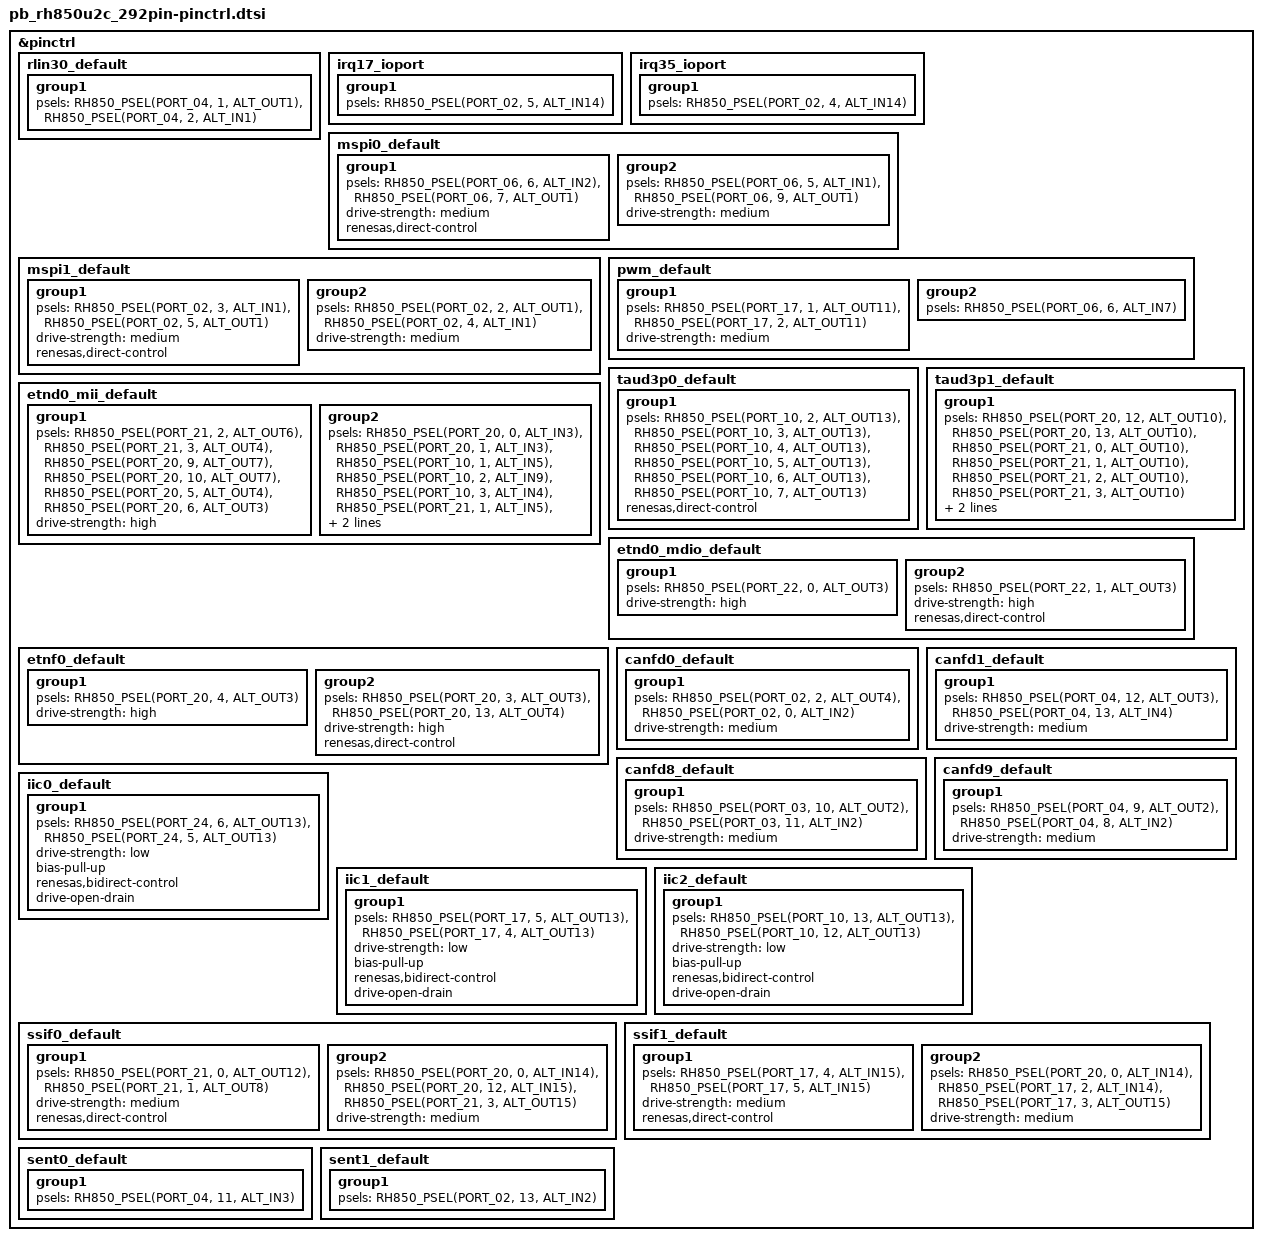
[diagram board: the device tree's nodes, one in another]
/*
 * Copyright (c) 2026 Renesas Electronics Corporation
 * SPDX-License-Identifier: Apache-2.0
 */

#include <dt-bindings/pinctrl/renesas/pinctrl-rh850u2c.h>

&pinctrl {
	rlin30_default: rlin30_default {
		group1 {
			psels = <RH850_PSEL(PORT_04, 1, ALT_OUT1)>,
				<RH850_PSEL(PORT_04, 2, ALT_IN1)>;
		};
	};

	irq17_ioport: irq17_ioport {
		group1 {
			psels = <RH850_PSEL(PORT_02, 5, ALT_IN14)>;
		};
	};

	irq35_ioport: irq35_ioport {
		group1 {
			psels = <RH850_PSEL(PORT_02, 4, ALT_IN14)>;
		};
	};

	mspi0_default: mspi0_default {
		group1 {
			psels = <RH850_PSEL(PORT_06, 6, ALT_IN2)>,
				<RH850_PSEL(PORT_06, 7, ALT_OUT1)>;
			drive-strength = "medium";
			renesas,direct-control;
		};

		group2 {
			psels = <RH850_PSEL(PORT_06, 5, ALT_IN1)>,
				<RH850_PSEL(PORT_06, 9, ALT_OUT1)>;
			drive-strength = "medium";
		};
	};

	mspi1_default: mspi1_default {
		group1 {
			psels = <RH850_PSEL(PORT_02, 3, ALT_IN1)>,
				<RH850_PSEL(PORT_02, 5, ALT_OUT1)>;
			drive-strength = "medium";
			renesas,direct-control;
		};

		group2 {
			psels = <RH850_PSEL(PORT_02, 2, ALT_OUT1)>,
				<RH850_PSEL(PORT_02, 4, ALT_IN1)>;
			drive-strength = "medium";
		};
	};

	pwm_default: pwm_default {
		group1 {
			psels = <RH850_PSEL(PORT_17, 1, ALT_OUT11)>,	/* ch1 */
				<RH850_PSEL(PORT_17, 2, ALT_OUT11)>;	/* ch2 */
			drive-strength = "medium";
		};

		group2 {
			psels = <RH850_PSEL(PORT_06, 6, ALT_IN7)>;	/* ch6 */
		};
	};

	taud3p0_default: taud3p0_default {
		group1 {
			psels = <RH850_PSEL(PORT_10, 2, ALT_OUT13)>,  /* U high */
				<RH850_PSEL(PORT_10, 3, ALT_OUT13)>,  /* U low  */
				<RH850_PSEL(PORT_10, 4, ALT_OUT13)>,  /* V high */
				<RH850_PSEL(PORT_10, 5, ALT_OUT13)>,  /* V low  */
				<RH850_PSEL(PORT_10, 6, ALT_OUT13)>,  /* W high */
				<RH850_PSEL(PORT_10, 7, ALT_OUT13)>;  /* W low  */
			renesas,direct-control;
		};
	};

	taud3p1_default: taud3p1_default {
		group1 {
			psels = <RH850_PSEL(PORT_20, 12, ALT_OUT10)>, /* U high */
				<RH850_PSEL(PORT_20, 13, ALT_OUT10)>, /* U low  */
				<RH850_PSEL(PORT_21, 0,  ALT_OUT10)>, /* V high */
				<RH850_PSEL(PORT_21, 1,  ALT_OUT10)>, /* V low  */
				<RH850_PSEL(PORT_21, 2,  ALT_OUT10)>, /* W high */
				<RH850_PSEL(PORT_21, 3,  ALT_OUT10)>; /* W low  */
			renesas,direct-control;
			drive-strength = "medium";
		};
	};

	etnd0_mii_default: etnd0_mii_default {
		group1 {
			psels = <RH850_PSEL(PORT_21, 2, ALT_OUT6)>,	/* ETH0_MII_TXD0 */
				<RH850_PSEL(PORT_21, 3, ALT_OUT4)>,	/* ETH0_MII_TXD1 */
				<RH850_PSEL(PORT_20, 9, ALT_OUT7)>,	/* ETH0_MII_TXD2 */
				<RH850_PSEL(PORT_20, 10, ALT_OUT7)>,	/* ETH0_MII_TXD3 */
				<RH850_PSEL(PORT_20, 5, ALT_OUT4)>,	/* ETH0_MII_TX_EN */
				<RH850_PSEL(PORT_20, 6, ALT_OUT3)>;	/* ETH0_MII_TX_ER */
			drive-strength = "high";
		};

		group2 {
			psels = <RH850_PSEL(PORT_20, 0, ALT_IN3)>,	/* ETH0_MII_RXD0 */
				<RH850_PSEL(PORT_20, 1, ALT_IN3)>,	/* ETH0_MII_RXD1 */
				<RH850_PSEL(PORT_10, 1, ALT_IN5)>,	/* ETH0_MII_RXD2 */
				<RH850_PSEL(PORT_10, 2, ALT_IN9)>,	/* ETH0_MII_RXD3 */
				<RH850_PSEL(PORT_10, 3, ALT_IN4)>,	/* ETH0_MII_RX_CLK */
				<RH850_PSEL(PORT_21, 1, ALT_IN5)>,	/* ETH0_MII_TX_CLK */
				<RH850_PSEL(PORT_20, 12, ALT_IN3)>,	/* ETH0_MII_RX_ER */
				<RH850_PSEL(PORT_20, 2, ALT_IN2)>;	/* ETH0_MII_RX_DV */
		};
	};

	etnd0_mdio_default: etnd0_mdio_default {
		group1 {
			psels = <RH850_PSEL(PORT_22, 0, ALT_OUT3)>; /* ETH0_MDC */
			drive-strength = "high";
		};

		group2 {
			psels = <RH850_PSEL(PORT_22, 1, ALT_OUT3)>; /* ETH0_MDIO */
			drive-strength = "high";
			renesas,direct-control;
		};
	};

	etnf0_default: etnf0_default {
		group1 {
			psels = <RH850_PSEL(PORT_20, 4, ALT_OUT3)>;
			drive-strength = "high";
		};

		group2 {
			psels = <RH850_PSEL(PORT_20, 3, ALT_OUT3)>,
				<RH850_PSEL(PORT_20, 13, ALT_OUT4)>;
			drive-strength = "high";
			renesas,direct-control;
		};
	};

	canfd0_default: canfd0_default {
		group1 {
			psels = <RH850_PSEL(PORT_02, 2, ALT_OUT4)>,	/* TX */
				<RH850_PSEL(PORT_02, 0, ALT_IN2)>;	/* RX */
			drive-strength = "medium";
		};
	};

	canfd1_default: canfd1_default {
		group1 {
			psels = <RH850_PSEL(PORT_04, 12, ALT_OUT3)>,	/* TX */
				<RH850_PSEL(PORT_04, 13, ALT_IN4)>;	/* RX */
			drive-strength = "medium";
		};
	};

	canfd8_default: canfd8_default {
		group1 {
			psels = <RH850_PSEL(PORT_03, 10, ALT_OUT2)>,	/* TX */
				<RH850_PSEL(PORT_03, 11, ALT_IN2)>;	/* RX */
			drive-strength = "medium";
		};
	};

	canfd9_default: canfd9_default {
		group1 {
			psels = <RH850_PSEL(PORT_04, 9, ALT_OUT2)>,	/* TX */
				<RH850_PSEL(PORT_04, 8, ALT_IN2)>;	/* RX */
			drive-strength = "medium";
		};
	};

	iic0_default: iic0_default {
		group1 {
			/* RI3C0SCL, RI3C0SDA */
			psels = <RH850_PSEL(PORT_24, 6, ALT_OUT13)>,
				<RH850_PSEL(PORT_24, 5, ALT_OUT13)>;
			drive-strength = "low";
			bias-pull-up;
			renesas,bidirect-control;
			drive-open-drain;
		};
	};

	iic1_default: iic1_default {
		group1 {
			/* RI3C1SCL, RI3C1SDA */
			psels = <RH850_PSEL(PORT_17, 5, ALT_OUT13)>,
				<RH850_PSEL(PORT_17, 4, ALT_OUT13)>;
			drive-strength = "low";
			bias-pull-up;
			renesas,bidirect-control;
			drive-open-drain;
		};
	};

	iic2_default: iic2_default {
		group1 {
			/* RI3C2SCL, RI3C2SDA */
			psels = <RH850_PSEL(PORT_10, 13, ALT_OUT13)>,
				<RH850_PSEL(PORT_10, 12, ALT_OUT13)>;
			drive-strength = "low";
			bias-pull-up;
			renesas,bidirect-control;
			drive-open-drain;
		};
	};

	ssif0_default: ssif0_default {
		group1 {
			psels = <RH850_PSEL(PORT_21, 0, ALT_OUT12)>,
				<RH850_PSEL(PORT_21, 1, ALT_OUT8)>;
			drive-strength = "medium";
			renesas,direct-control;
		};

		group2 {
			psels = <RH850_PSEL(PORT_20, 0, ALT_IN14)>,
				<RH850_PSEL(PORT_20, 12, ALT_IN15)>,
				<RH850_PSEL(PORT_21, 3, ALT_OUT15)>;
			drive-strength = "medium";
		};
	};

	ssif1_default: ssif1_default {
		group1 {
			psels = <RH850_PSEL(PORT_17, 4, ALT_IN15)>,
				<RH850_PSEL(PORT_17, 5, ALT_IN15)>;
			drive-strength = "medium";
			renesas,direct-control;
		};

		group2 {
			psels = <RH850_PSEL(PORT_20, 0, ALT_IN14)>,
				<RH850_PSEL(PORT_17, 2, ALT_IN14)>,
				<RH850_PSEL(PORT_17, 3, ALT_OUT15)>;
			drive-strength = "medium";
		};
	};

	sent0_default: sent0_default {
		group1 {
			psels = <RH850_PSEL(PORT_04, 11, ALT_IN3)>;
		};
	};

	sent1_default: sent1_default {
		group1 {
			psels = <RH850_PSEL(PORT_02, 13, ALT_IN2)>;
		};
	};
};
